# STM32WLE5 register map
File version: 1.6
CPU: CM4 r0p1, little endian, MPU, no FPU, 4 interrupt priority bits
Registers are 32-bit, read-write, reset 0x0 unless marked. A register's access mark holds for its fields unless they carry their own. Offsets are from the block's base; [hi:lo] are bit positions; lines under a group give offsets from that group; {n}, {i} and the like mark numbered series; 'fields as' and 'values as' point back to an identical list.

## CRC — Cyclic redundancy check calculation unit
Base 0x40023000
0x00 DR reset 0xFFFFFFFF — Data register
  [31:0] DR — Data register bits
0x00 DR8 8-bit reset 0xFF (alternate view of DR) — Data register - byte sized
  [7:0] DR8 — Data register bits
0x00 DR16 16-bit reset 0xFFFF (alternate view of DR) — Data register - half-word sized
  [15:0] DR16 — Data register bits
0x04 IDR — Independent data register
  [31:0] IDR — General-purpose 32-bit data register bits
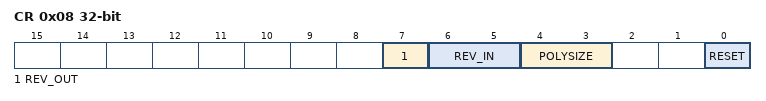
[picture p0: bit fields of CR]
0x08 CR — Control register
  [7] REV_OUT — Reverse output data
    0=Normal (Bit order not affected); 1=Reversed (Bit reversed output)
  [6:5] REV_IN — Reverse input data
    0=Normal (Bit order not affected); 1=Byte (Bit reversal done by byte); 2=HalfWord (Bit reversal done by half-word); 3=Word (Bit reversal done by word)
  [4:3] POLYSIZE — Polynomial size
    0=32-bit polynomial; 1=16-bit polynomial; 2=8-bit polynomial; 3=7-bit polynomial
  [0] RESET — RESET bit
    on write: 1=Resets the CRC calculation unit and sets the data register to 0xFFFF FFFF
0x10 INIT reset 0xFFFFFFFF — Initial CRC value
  [31:0] INIT — Programmable initial CRC value
0x14 POL reset 0x4C11DB7 — polynomial
  [31:0] POL — Programmable polynomial

## DBGMCU — Microcontroller Debug Unit
Base 0xE0042000
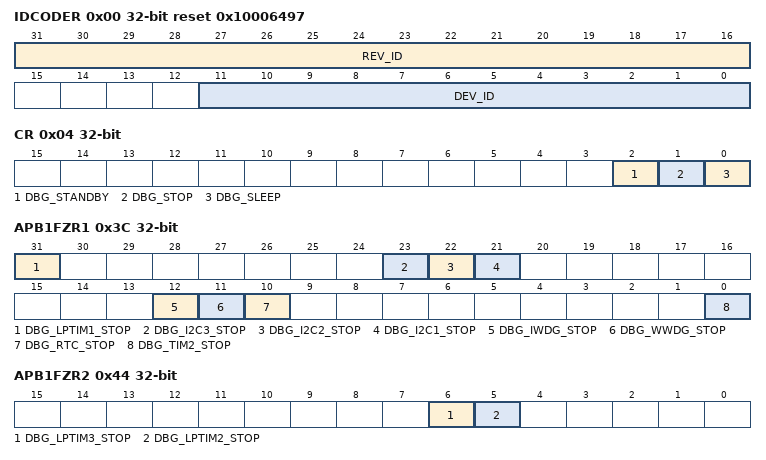
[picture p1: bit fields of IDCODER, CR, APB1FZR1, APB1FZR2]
0x00 IDCODER ro reset 0x10006497 — DBGMCU Identity Code Register
  [31:16] REV_ID — Revision
  [11:0] DEV_ID — Device ID
0x04 CR — DBGMCU Configuration Register
  [2] DBG_STANDBY — Allow debug in STANDBY mode
    0=Disabled (Debug Standby Mode Disabled); 1=Enabled (Debug Standby Mode Enabled)
  [1] DBG_STOP — Allow debug in STOP mode
    0=Disabled (Debug Stop Mode Disabled); 1=Enabled (Debug Stop Mode Enabled)
  [0] DBG_SLEEP — Allow debug in SLEEP mode
    0=Disabled (Debug Sleep Mode Disabled); 1=Enabled (Debug Sleep Mode Enabled)
0x3C APB1FZR1 — DBGMCU CPU1 APB1 Peripheral Freeze Register 1
  [31] DBG_LPTIM1_STOP — LPTIM1 stop in CPU1 debug
    0=Continue (LPTIMx counter clock is fed even if the core is halted); 1=Stop (LPTIMx counter clock is stopped when the core is halted)
  [23] DBG_I2C3_STOP — I2C3 SMBUS timeout stop in CPU1 debug
    0=NormalMode (Same behavior as in normal mode); 1=SMBusTimeoutFrozen (I2Cx SMBUS timeout is frozen)
  [22] DBG_I2C2_STOP — I2C2 SMBUS timeout stop in CPU1 debug
    values as DBG_I2C3_STOP
  [21] DBG_I2C1_STOP — I2C1 SMBUS timeout stop in CPU1 debug
    values as DBG_I2C3_STOP
  [12] DBG_IWDG_STOP — IWDG stop in CPU1 debug
    0=Continue (The independent watchdog counter clock continues even if the core is halted); 1=Stop (The independent watchdog counter clock is stopped when the core is halted)
  [11] DBG_WWDG_STOP — WWDG stop in CPU1 debug
    0=Continue (The window watchdog counter clock continues even if the core is halted); 1=Stop (The window watchdog counter clock is stopped when the core is halted)
  [10] DBG_RTC_STOP — RTC stop in CPU1 debug
    0=Continue (The clock of the RTC counter is fed even if the core is halted); 1=Stop (The clock of the RTC counter is stopped when the core is halted)
  [0] DBG_TIM2_STOP — TIM2 stop in CPU1 debug
    0=Continue (The counter clock of TIMx is fed even if the core is halted); 1=Stop (The counter clock of TIMx is stopped when the core is halted)
0x44 APB1FZR2 — DBGMCU CPU1 APB1 Peripheral Freeze Register 2
  [6] DBG_LPTIM3_STOP
    values as APB1FZR1.DBG_LPTIM1_STOP
  [5] DBG_LPTIM2_STOP
    values as APB1FZR1.DBG_LPTIM1_STOP
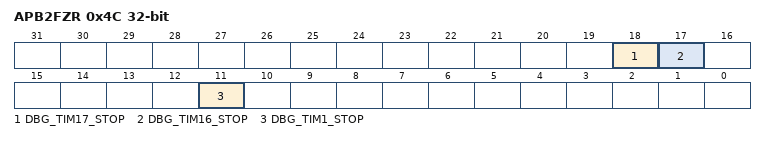
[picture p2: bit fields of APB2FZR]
0x4C APB2FZR — DBGMCU CPU1 APB2 Peripheral Freeze Register
  [all] fields
    values as APB1FZR1.DBG_TIM2_STOP
  [18] DBG_TIM17_STOP
  [17] DBG_TIM16_STOP
  [11] DBG_TIM1_STOP

## DMA1 — Direct memory access controller
Base 0x40020000
Same registers: DMA2 0x40020400
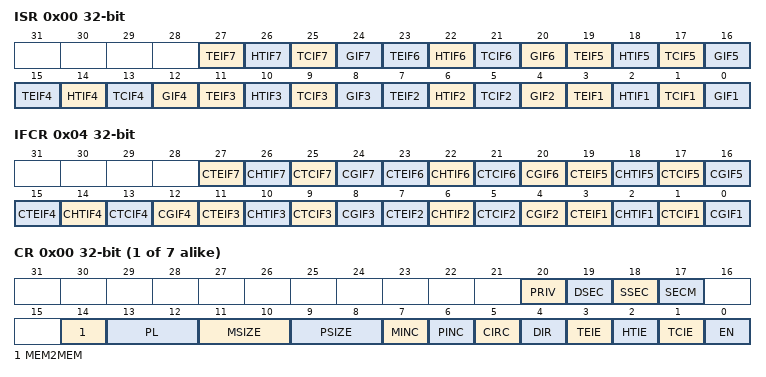
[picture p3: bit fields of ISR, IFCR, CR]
0x00 ISR ro — interrupt status register
  [4n-1] TEIF{n} (n=1..7) — Channel {n} Transfer Error flag
    0=NoError (No transfer error); 1=Error (A transfer error has occured)
  [4n-2] HTIF{n} (n=1..7) — Channel {n} Half Transfer Complete flag
    0=NotHalf (No half transfer event); 1=Half (A half transfer event has occured)
  [4n-3] TCIF{n} (n=1..7) — Channel {n} Transfer Complete flag
    0=NotComplete (No transfer complete event); 1=Complete (A transfer complete event has occured)
  [4n-4] GIF{n} (n=1..7) — Channel {n} Global interrupt flag
    0=NoEvent (No transfer error, half event, complete event); 1=Event (A transfer error, half event or complete event has occured)
0x04 IFCR wo — interrupt flag clear register
  [4n-1] CTEIF{n} (n=1..7) — Channel {n} Transfer Error clear
    1=Clears the TEIF flag in the ISR register
  [4n-2] CHTIF{n} (n=1..7) — Channel {n} Half Transfer clear
    1=Clears the HTIF flag in the ISR register
  [4n-3] CTCIF{n} (n=1..7) — Channel {n} Transfer Complete clear
    1=Clears the TCIF flag in the ISR register
  [4n-4] CGIF{n} (n=1..7) — Channel {n} Global interrupt clear
    1=Clears the GIF, TEIF, HTIF, TCIF flags in the ISR register
0x08 CH{i} (i=1..7; step 0x14) group — Channel cluster: CCR?, CNDTR?, CPAR?, and CMAR? registers
  0x00 CR — channel x configuration register
    [20] PRIV — rivileged mode
      0=Disabled; 1=Enabled
    [19] DSEC — ecurity of the DMA transfer to the destination
    [18] SSEC — ecurity of the DMA transfer from the source
    [17] SECM — ecure mode
    [14] MEM2MEM — memory-to-memory mode
      0=Disabled (Memory to memory mode disabled); 1=Enabled (Memory to memory mode enabled)
    [13:12] PL — priority level
      0=Low (Low priority); 1=Medium priority; 2=High priority; 3=Very high priority
    [11:10] MSIZE — memory size
      0=Bits8 (8-bit size); 1=Bits16 (16-bit size); 2=Bits32 (32-bit size)
    [9:8] PSIZE — peripheral size
      values as MSIZE
    [7] MINC — memory increment mode
      0=Disabled (Increment mode disabled); 1=Enabled (Increment mode enabled)
    [6] PINC — peripheral increment mode
      values as MINC
    [5] CIRC — circular mode
      0=Disabled (Circular buffer disabled); 1=Enabled (Circular buffer enabled)
    [4] DIR — data transfer direction
      0=FromPeripheral (Read from peripheral); 1=FromMemory (Read from memory)
    [3] TEIE — transfer error interrupt enable
      0=Disabled (Transfer Error interrupt disabled); 1=Enabled (Transfer Error interrupt enabled)
    [2] HTIE — half transfer interrupt enable
      0=Disabled (Half Transfer interrupt disabled); 1=Enabled (Half Transfer interrupt enabled)
    [1] TCIE — transfer complete interrupt enable
      0=Disabled (Transfer Complete interrupt disabled); 1=Enabled (Transfer Complete interrupt enabled)
    [0] EN — channel enable
      0=Disabled (Channel disabled); 1=Enabled (Channel enabled)
  0x04 NDTR — channel x number of data to transfer register
    [17:0] NDT — number of data to transfer (0 to 218 - 1)
  0x08 PAR — channel x peripheral address register
    [31:0] PA — peripheral address
  0x0C MAR — channel x memory address register
    [31:0] MA — peripheral address
